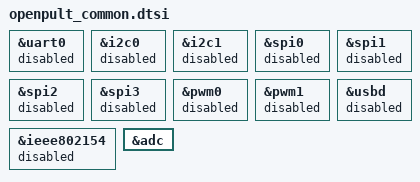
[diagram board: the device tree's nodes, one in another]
/*
 * Shared by all board overlays: switch off every peripheral the bridge does not use,
 * so no driver initialises it and nothing draws current in idle.
 * debug.overlay re-enables USB for the debug build.
 */

#include <zephyr/dt-bindings/gpio/nordic-nrf-gpio.h>

&uart0 {
	status = "disabled";
};

&i2c0 {
	status = "disabled";
};

&i2c1 {
	status = "disabled";
};

&spi0 {
	status = "disabled";
};

&spi1 {
	status = "disabled";
};

&spi2 {
	status = "disabled";
};

&spi3 {
	status = "disabled";
};

/* pwm1 is the IR carrier generator (see ir-pwm) and must not get a Zephyr driver. */
&pwm0 {
	status = "disabled";
};

&pwm1 {
	status = "disabled";
};

&usbd {
	status = "disabled";
};

&ieee802154 {
	status = "disabled";
};

&adc {
	status = "okay";
	#address-cells = <1>;
	#size-cells = <0>;
};

/*
 * DC/DC regulators: lower idle and radio current, but only work if the board has the
 * inductors (REG0: on DCCH, REG1: between DCC and DEC4). Enabling them on a board
 * without the inductors leaves the chip unpowered until it is reflashed through the
 * bootloader. Check the schematic of your board first.
 *
 * &reg0 {
 *	status = "okay";
 * };
 *
 * &reg1 {
 *	regulator-initial-mode = <NRF5X_REG_MODE_DCDC>;
 * };
 */

/*
 * 32.768 kHz source. Some clone boards ship with a dead or missing crystal: the
 * firmware then hangs at boot waiting for LFXO. Switching to the internal RC
 * oscillator fixes that at the cost of periodic calibration (a few uA more).
 * (In Zephyr 4.5 this replaces CONFIG_CLOCK_CONTROL_NRF_K32SRC_RC of the legacy
 * clock driver.)
 *
 * &lfclk {
 *	k32src = "rc";
 *	k32src-accuracy-ppm = <500>;
 * };
 */
